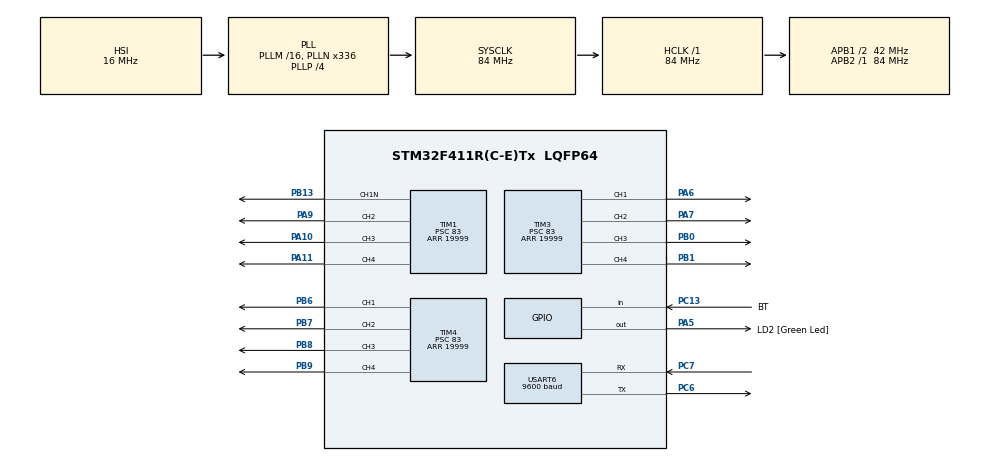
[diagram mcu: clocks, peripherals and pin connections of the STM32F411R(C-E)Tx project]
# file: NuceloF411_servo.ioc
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FREERTOS.Tasks01=defaultTask,24,128,StartDefaultTask,Default,NULL,Dynamic,NULL,NULL
FREERTOS.configUSE_NEWLIB_REENTRANT=1
Mcu.Family=STM32F4
Mcu.Name=STM32F411R(C-E)Tx
Mcu.Package=LQFP64
NVIC.PriorityGroup=NVIC_PRIORITYGROUP_4
NVIC.TIM1_TRG_COM_TIM11_IRQn=true\:5\:0\:false\:false\:true\:false\:false\:true\:true
NVIC.TimeBase=TIM1_TRG_COM_TIM11_IRQn
NVIC.TimeBaseIP=TIM11
NVIC.USART6_IRQn=true\:5\:0\:false\:false\:true\:true\:true\:true\:true
PA10.Signal=S_TIM1_CH3
PA11.Signal=S_TIM1_CH4
PA13.GPIO_Label=TMS
PA13.Mode=Serial_Wire
PA13.Signal=SYS_JTMS-SWDIO
PA14.GPIO_Label=TCK
PA14.Mode=Serial_Wire
PA14.Signal=SYS_JTCK-SWCLK
PA5.GPIO_Label=LD2 [Green Led]
PA5.Signal=GPIO_Output
PA6.Signal=S_TIM3_CH1
PA7.Signal=S_TIM3_CH2
PA9.Signal=S_TIM1_CH2
PB0.Signal=S_TIM3_CH3
PB1.Signal=S_TIM3_CH4
PB13.Mode=PWM Generation1 CH1N
PB13.Signal=TIM1_CH1N
PB3.GPIO_Label=SWO
PB3.Signal=SYS_JTDO-SWO
PB6.Signal=S_TIM4_CH1
PB7.Signal=S_TIM4_CH2
PB8.Signal=S_TIM4_CH3
PB9.Signal=S_TIM4_CH4
PC13-ANTI_TAMP.GPIO_Label=BT
PC13-ANTI_TAMP.Signal=GPIO_Input
PC14-OSC32_IN.Signal=RCC_OSC32_IN
PC15-OSC32_OUT.Signal=RCC_OSC32_OUT
PC6.Mode=Asynchronous
PC6.Signal=USART6_TX
PC7.Mode=Asynchronous
PC7.Signal=USART6_RX
PH0\ -\ OSC_IN.Mode=HSE-External-Oscillator
PH0\ -\ OSC_IN.Signal=RCC_OSC_IN
PH1\ -\ OSC_OUT.Mode=HSE-External-Oscillator
PH1\ -\ OSC_OUT.Signal=RCC_OSC_OUT
ProjectManager.HeapSize=0x200
ProjectManager.StackSize=0x400
ProjectManager.TargetToolchain=STM32CubeIDE
RCC.48MHZClocksFreq_Value=84000000
RCC.AHBFreq_Value=84000000
RCC.APB1CLKDivider=RCC_HCLK_DIV2
RCC.APB1Freq_Value=42000000
RCC.APB1TimFreq_Value=84000000
RCC.APB2Freq_Value=84000000
RCC.APB2TimFreq_Value=84000000
RCC.CortexFreq_Value=84000000
RCC.FLatency-AdvancedSettings=FLASH_LATENCY_2
RCC.HCLKFreq_Value=84000000
RCC.HSE_VALUE=8000000
RCC.HSI_VALUE=16000000
RCC.LSE_VALUE=32768
RCC.PLLN=336
RCC.PLLP=RCC_PLLP_DIV4
RCC.SYSCLKFreq_VALUE=84000000
RCC.SYSCLKSource=RCC_SYSCLKSOURCE_PLLCLK
RCC.VCOOutputFreq_Value=336000000
SH.S_TIM1_CH2.0=TIM1_CH2,PWM Generation2 CH2
SH.S_TIM1_CH3.0=TIM1_CH3,PWM Generation3 CH3
SH.S_TIM1_CH4.0=TIM1_CH4,PWM Generation4 CH4
SH.S_TIM3_CH1.0=TIM3_CH1,PWM Generation1 CH1
SH.S_TIM3_CH2.0=TIM3_CH2,PWM Generation2 CH2
SH.S_TIM3_CH3.0=TIM3_CH3,PWM Generation3 CH3
SH.S_TIM3_CH4.0=TIM3_CH4,PWM Generation4 CH4
SH.S_TIM4_CH1.0=TIM4_CH1,PWM Generation1 CH1
SH.S_TIM4_CH2.0=TIM4_CH2,PWM Generation2 CH2
SH.S_TIM4_CH3.0=TIM4_CH3,PWM Generation3 CH3
SH.S_TIM4_CH4.0=TIM4_CH4,PWM Generation4 CH4
TIM1.Channel-PWM\ Generation1\ CH1N=TIM_CHANNEL_1
TIM1.Channel-PWM\ Generation2\ CH2=TIM_CHANNEL_2
TIM1.Channel-PWM\ Generation3\ CH3=TIM_CHANNEL_3
TIM1.Channel-PWM\ Generation4\ CH4=TIM_CHANNEL_4
TIM1.Period=19999
TIM1.Prescaler=83
TIM3.Channel-PWM\ Generation1\ CH1=TIM_CHANNEL_1
TIM3.Channel-PWM\ Generation2\ CH2=TIM_CHANNEL_2
TIM3.Channel-PWM\ Generation3\ CH3=TIM_CHANNEL_3
TIM3.Channel-PWM\ Generation4\ CH4=TIM_CHANNEL_4
TIM3.Period=19999
TIM3.Prescaler=83
TIM4.Channel-PWM\ Generation1\ CH1=TIM_CHANNEL_1
TIM4.Channel-PWM\ Generation2\ CH2=TIM_CHANNEL_2
TIM4.Channel-PWM\ Generation3\ CH3=TIM_CHANNEL_3
TIM4.Channel-PWM\ Generation4\ CH4=TIM_CHANNEL_4
TIM4.Period=19999
TIM4.Prescaler=83
USART6.BaudRate=9600
USART6.VirtualMode=VM_ASYNC
VP_FREERTOS_VS_CMSIS_V2.Mode=CMSIS_V2
VP_SYS_VS_tim11.Mode=TIM11
VP_TIM1_VS_ClockSourceINT.Mode=Internal
VP_TIM3_VS_ClockSourceINT.Mode=Internal
VP_TIM4_VS_ClockSourceINT.Mode=Internal
board=NUCLEO-F411RE

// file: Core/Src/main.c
/* USER CODE BEGIN Header */
/**
  ******************************************************************************
  * @file           : main.c
  * @brief          : Main program body
  ******************************************************************************
  * @attention
  *
  * Copyright (c) 2022 STMicroelectronics.
  * All rights reserved.
  *
  * This software is licensed under terms that can be found in the LICENSE file
  * in the root directory of this software component.
  * If no LICENSE file comes with this software, it is provided AS-IS.
  *
  ******************************************************************************
  */
/* USER CODE END Header */
#include "main.h"
#include "cmsis_os.h"
#include "tim.h"
#include "usart.h"
#include "gpio.h"

/* USER CODE BEGIN Includes */
#include "servo.h"
#include "handle_interrupt.h"
#include "service_uart.h"
/* USER CODE END Includes */

void SystemClock_Config(void);
void MX_FREERTOS_Init(void);

int main(void)
{

  /* MCU Configuration--------------------------------------------------------*/

  /* Reset of all peripherals, Initializes the Flash interface and the Systick. */
  HAL_Init();

  /* Configure the system clock */
  SystemClock_Config();

  /* Initialize all configured peripherals */
  MX_GPIO_Init();
  MX_TIM3_Init();
  MX_TIM4_Init();
  MX_TIM1_Init();
  MX_USART6_UART_Init();
  /* USER CODE BEGIN 2 */
  handle_AUX_signal_init();
  servo_init();
  init_service_uart();
  /* USER CODE END 2 */

  /* Init scheduler */
  osKernelInitialize();  /* Call init function for freertos objects (in freertos.c) */
  MX_FREERTOS_Init();

  /* Start scheduler */
  osKernelStart();

  /* We should never get here as control is now taken by the scheduler */
  /* Infinite loop */
  while (1)
  {

  }
}

void SystemClock_Config(void)
{
  RCC_OscInitTypeDef RCC_OscInitStruct = {0};
  RCC_ClkInitTypeDef RCC_ClkInitStruct = {0};

  /** Configure the main internal regulator output voltage
  */
  __HAL_RCC_PWR_CLK_ENABLE();
  __HAL_PWR_VOLTAGESCALING_CONFIG(PWR_REGULATOR_VOLTAGE_SCALE1);

  /** Initializes the RCC Oscillators according to the specified parameters
  * in the RCC_OscInitTypeDef structure.
  */
  RCC_OscInitStruct.OscillatorType = RCC_OSCILLATORTYPE_HSI;
  RCC_OscInitStruct.HSIState = RCC_HSI_ON;
  RCC_OscInitStruct.HSICalibrationValue = RCC_HSICALIBRATION_DEFAULT;
  RCC_OscInitStruct.PLL.PLLState = RCC_PLL_ON;
  RCC_OscInitStruct.PLL.PLLSource = RCC_PLLSOURCE_HSI;
  RCC_OscInitStruct.PLL.PLLM = 16;
  RCC_OscInitStruct.PLL.PLLN = 336;
  RCC_OscInitStruct.PLL.PLLP = RCC_PLLP_DIV4;
  RCC_OscInitStruct.PLL.PLLQ = 4;
  if (HAL_RCC_OscConfig(&RCC_OscInitStruct) != HAL_OK)
  {
    Error_Handler();
  }

  /** Initializes the CPU, AHB and APB buses clocks
  */
  RCC_ClkInitStruct.ClockType = RCC_CLOCKTYPE_HCLK|RCC_CLOCKTYPE_SYSCLK
                              |RCC_CLOCKTYPE_PCLK1|RCC_CLOCKTYPE_PCLK2;
  RCC_ClkInitStruct.SYSCLKSource = RCC_SYSCLKSOURCE_PLLCLK;
  RCC_ClkInitStruct.AHBCLKDivider = RCC_SYSCLK_DIV1;
  RCC_ClkInitStruct.APB1CLKDivider = RCC_HCLK_DIV2;
  RCC_ClkInitStruct.APB2CLKDivider = RCC_HCLK_DIV1;

  if (HAL_RCC_ClockConfig(&RCC_ClkInitStruct, FLASH_LATENCY_2) != HAL_OK)
  {
    Error_Handler();
  }
}

void HAL_TIM_PeriodElapsedCallback(TIM_HandleTypeDef *htim)
{
  if (htim->Instance == TIM11) {
    HAL_IncTick();
  }
}

void Error_Handler(void)
{
  __disable_irq();
  while (1)
  {
  }
}
